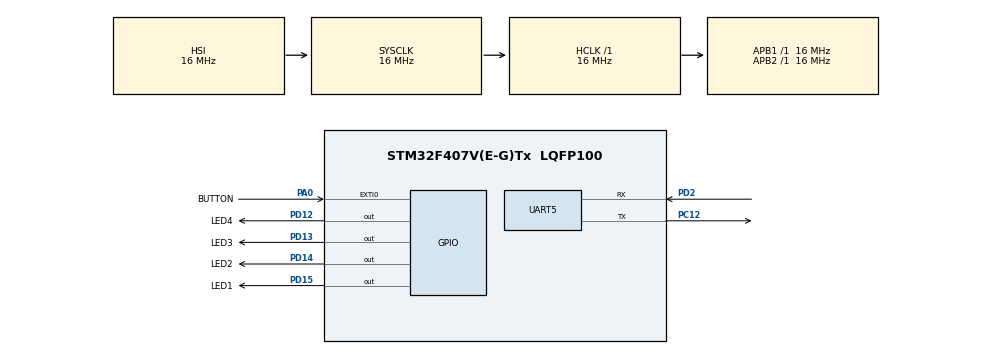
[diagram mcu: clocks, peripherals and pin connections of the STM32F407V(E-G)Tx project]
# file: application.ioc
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Mcu.Family=STM32F4
PD12.GPIO_Label=LED4
RCC.CortexFreq_Value=16000000
PD15.GPIO_Label=LED1
PC12.Signal=UART5_TX
UART5.VirtualMode=Asynchronous
ProjectManager.StackSize=0x400
PA0-WKUP.GPIO_Label=BUTTON
PA0-WKUP.Signal=GPXTI0
PD13.Signal=GPIO_Output
ProjectManager.TargetToolchain=STM32CubeIDE
RCC.LSE_VALUE=32768
RCC.AHBFreq_Value=16000000
PD2.Mode=Asynchronous
RCC.HSE_VALUE=25000000
PC12.Mode=Asynchronous
board=custom
RCC.VCOOutputFreq_Value=192000000
RCC.APB2Freq_Value=16000000
PD14.GPIO_Label=LED2
Mcu.Name=STM32F407V(E-G)Tx
PD14.Signal=GPIO_Output
RCC.SYSCLKFreq_VALUE=16000000
PD13.GPIO_Label=LED3
Mcu.Package=LQFP100
PD12.Signal=GPIO_Output
ProjectManager.HeapSize=0x200
RCC.HSI_VALUE=16000000
NVIC.PriorityGroup=NVIC_PRIORITYGROUP_4
PD2.Signal=UART5_RX
RCC.APB1Freq_Value=16000000
PD15.Signal=GPIO_Output

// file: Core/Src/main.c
/* USER CODE BEGIN Header */
/**
  ******************************************************************************
  * @file           : main.c
  * @brief          : Main program body
  ******************************************************************************
  * @attention
  *
  * <h2><center>&copy; Copyright (c) 2022 STMicroelectronics.
  * All rights reserved.</center></h2>
  *
  * This software component is licensed by ST under BSD 3-Clause license,
  * the "License"; You may not use this file except in compliance with the
  * License. You may obtain a copy of the License at:
  *                        opensource.org/licenses/BSD-3-Clause
  *
  ******************************************************************************
  */
/* USER CODE END Header */
#include "main.h"
#include "usart.h"
#include "gpio.h"

/* USER CODE BEGIN Includes */
#include "stdio.h"
/* USER CODE END Includes */

void SystemClock_Config(void);

int main(void)
{

  /* MCU Configuration--------------------------------------------------------*/

  /* Reset of all peripherals, Initializes the Flash interface and the Systick. */
  HAL_Init();

  /* Configure the system clock */
  SystemClock_Config();

  /* Initialize all configured peripherals */
  MX_GPIO_Init();
  MX_UART5_Init();
  /* USER CODE BEGIN 2 */
  printf("Starting Application\r\n" );
  /* USER CODE END 2 */

  /* Infinite loop */
  while (1)
  {

    /* USER CODE BEGIN 3 */
	HAL_GPIO_TogglePin(LED2_GPIO_Port, LED2_Pin|LED3_Pin|LED4_Pin);
	HAL_Delay(500);
  }
  /* USER CODE END 3 */
}

void SystemClock_Config(void)
{
  RCC_OscInitTypeDef RCC_OscInitStruct = {0};
  RCC_ClkInitTypeDef RCC_ClkInitStruct = {0};

  /** Configure the main internal regulator output voltage
  */
  __HAL_RCC_PWR_CLK_ENABLE();
  __HAL_PWR_VOLTAGESCALING_CONFIG(PWR_REGULATOR_VOLTAGE_SCALE1);
  /** Initializes the RCC Oscillators according to the specified parameters
  * in the RCC_OscInitTypeDef structure.
  */
  RCC_OscInitStruct.OscillatorType = RCC_OSCILLATORTYPE_HSI;
  RCC_OscInitStruct.HSIState = RCC_HSI_ON;
  RCC_OscInitStruct.HSICalibrationValue = RCC_HSICALIBRATION_DEFAULT;
  RCC_OscInitStruct.PLL.PLLState = RCC_PLL_NONE;
  if (HAL_RCC_OscConfig(&RCC_OscInitStruct) != HAL_OK)
  {
    Error_Handler();
  }
  /** Initializes the CPU, AHB and APB buses clocks
  */
  RCC_ClkInitStruct.ClockType = RCC_CLOCKTYPE_HCLK|RCC_CLOCKTYPE_SYSCLK
                              |RCC_CLOCKTYPE_PCLK1|RCC_CLOCKTYPE_PCLK2;
  RCC_ClkInitStruct.SYSCLKSource = RCC_SYSCLKSOURCE_HSI;
  RCC_ClkInitStruct.AHBCLKDivider = RCC_SYSCLK_DIV1;
  RCC_ClkInitStruct.APB1CLKDivider = RCC_HCLK_DIV1;
  RCC_ClkInitStruct.APB2CLKDivider = RCC_HCLK_DIV1;

  if (HAL_RCC_ClockConfig(&RCC_ClkInitStruct, FLASH_LATENCY_0) != HAL_OK)
  {
    Error_Handler();
  }
}

/* USER CODE BEGIN 4 */
/**
  * @brief Print the characters to UART (printf).
  * @retval int
  */
#ifdef __GNUC__
  /* With GCC, small printf (option LD Linker->Libraries->Small printf
     set to 'Yes') calls __io_putchar() */
int __io_putchar(int ch)
#else
int fputc(int ch, FILE *f)
#endif /* __GNUC__ */
{
  /* Place your implementation of fputc here */
  /* e.g. write a character to the UART3 and Loop until the end of transmission */
  HAL_UART_Transmit(&huart5, (uint8_t *)&ch, 1, HAL_MAX_DELAY);

  return ch;
}
/* USER CODE END 4 */

void Error_Handler(void)
{
  __disable_irq();
  while (1)
  {
  }
}

/************************ (C) COPYRIGHT STMicroelectronics *****END OF FILE****/
